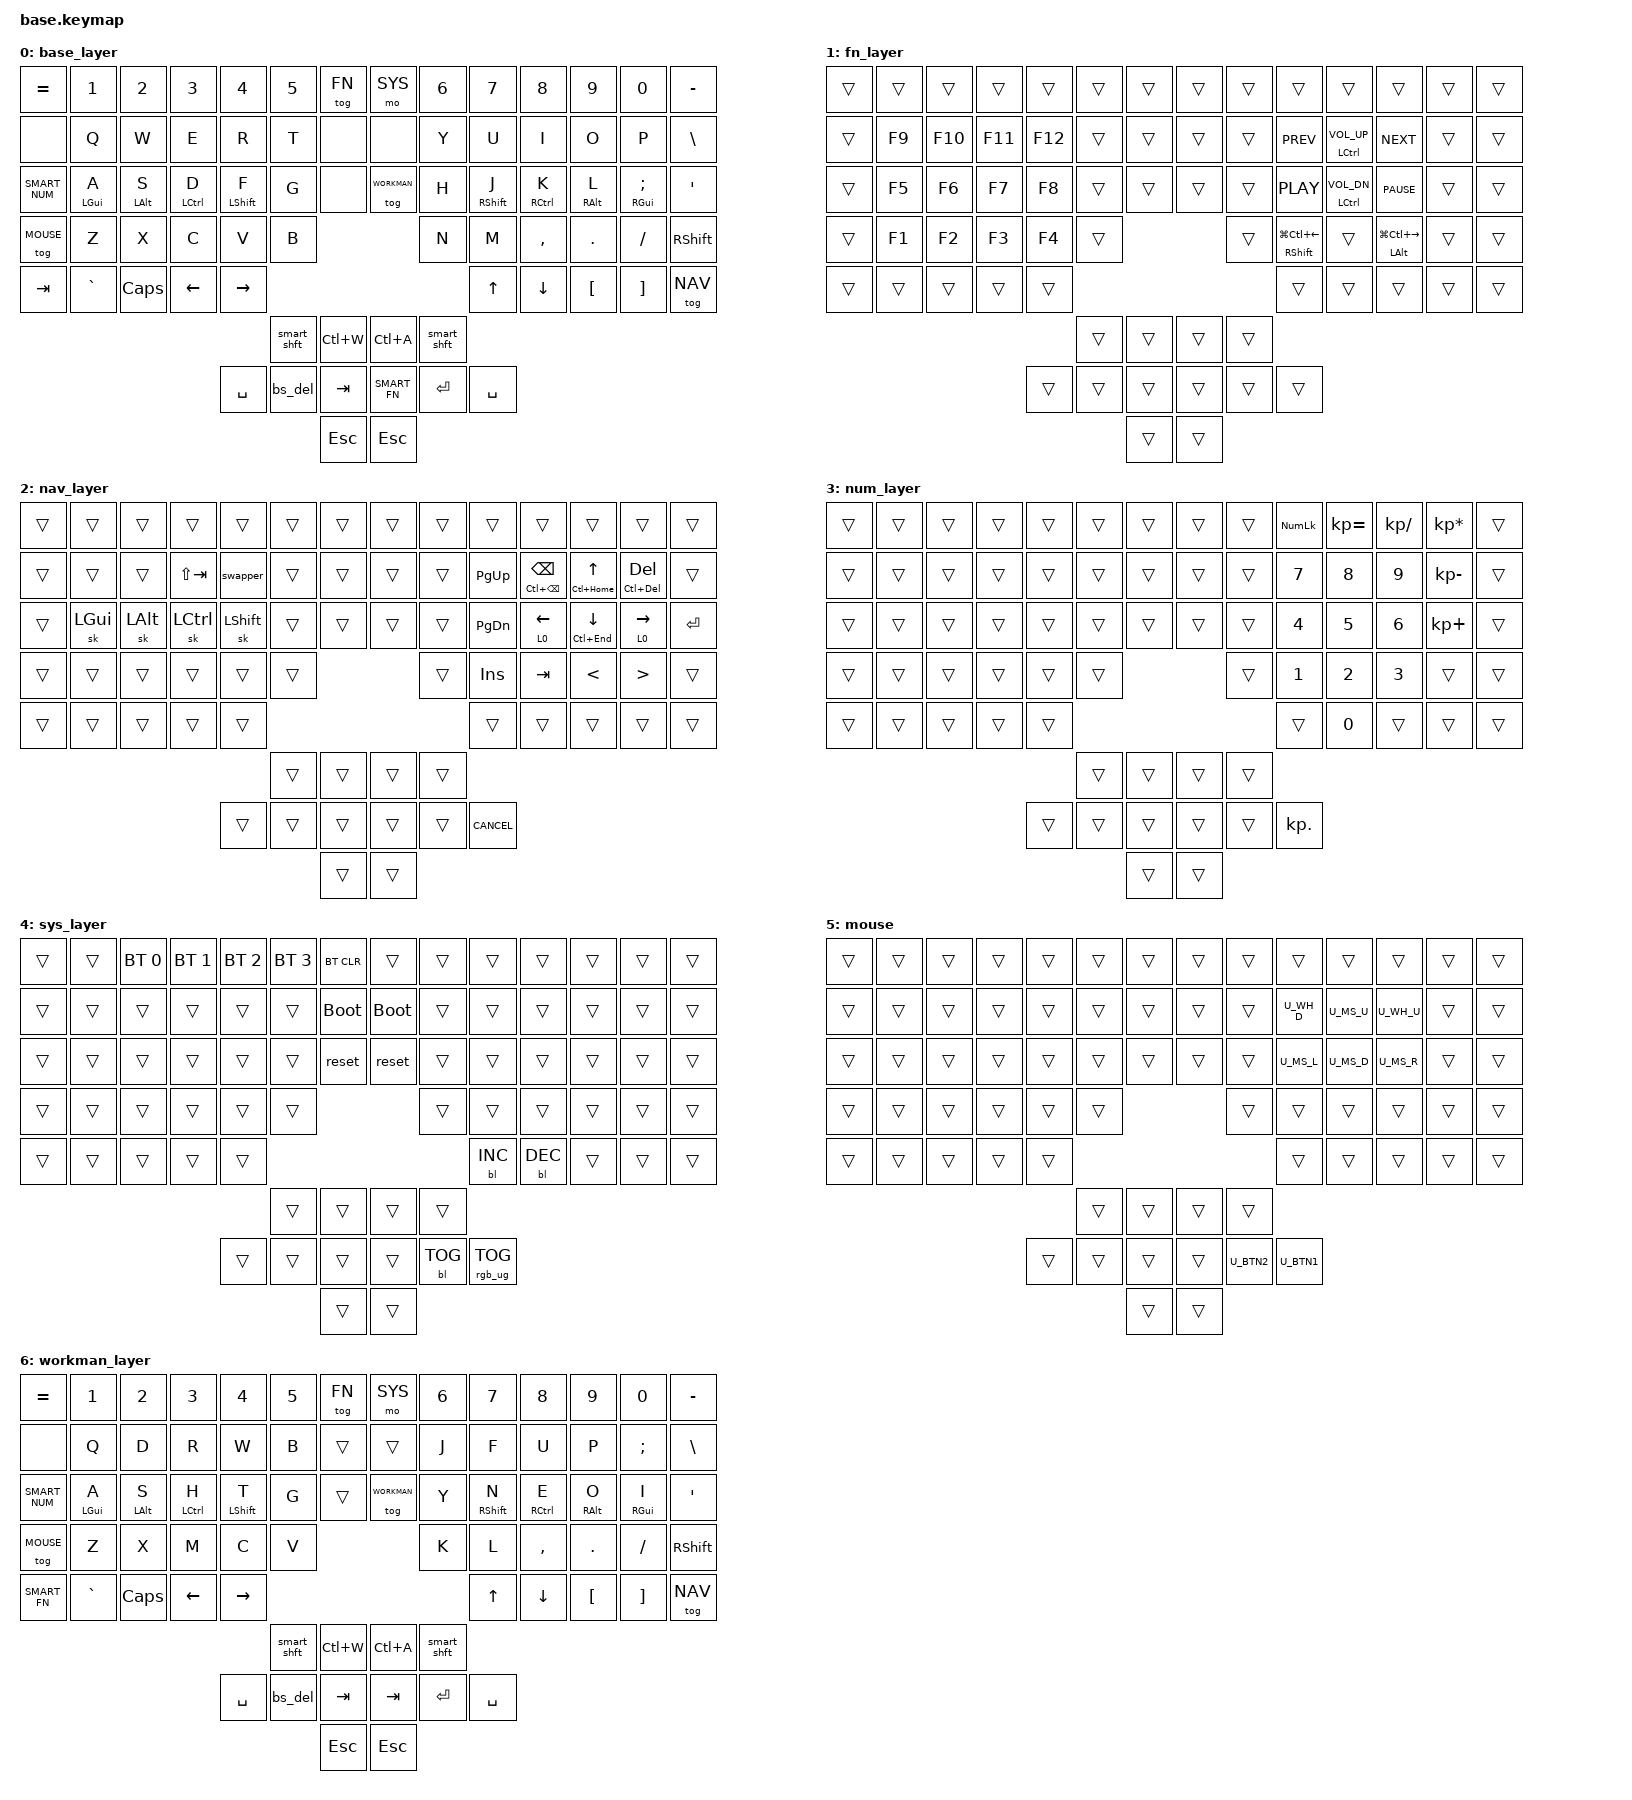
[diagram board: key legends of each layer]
#include <behaviors.dtsi>
#include <dt-bindings/zmk/keys.h>
#if CONFIG_WIRELESS
    #include <dt-bindings/zmk/bt.h>
    #define _BT_SEL_KEYS_ &bt BT_SEL 0 &bt BT_SEL 1 &bt BT_SEL 2 &bt BT_SEL 3 &bt BT_CLR
#else
    #define _BT_SEL_KEYS_ &trans &trans &trans &trans &trans
#endif

#include "../zmk-nodefree-config/helper.h"
#include "../zmk-nodefree-config/international_chars/greek.dtsi"
#include "../zmk-nodefree-config/international_chars/german.dtsi"

#define XXX &none
#define ___ &trans

/* Global settings */

#define QUICK_TAP_MS 175

#define DEF 0
#define FN 1
#define NAV 2
#define NUM 3
#define SYS 4
#define MOUSE 5
#define WORKMAN 6

#include "extra_keys.h"

#include "behaviours/morphs.dtsi"
#include "behaviours/tap_dance.dtsi"

#include "behaviours/smart_mouse.dtsi"
#include "behaviours/smart_num.dtsi"
#include "behaviours/smart_shift.dtsi"
#include "behaviours/smart_fn.dtsi"

#include "mouse.dtsi"

&sk {  // sticky-key config
    release-after-ms = <900>;  // release after 0.6s
    quick-release;             // no double capitalization when rolling keys
};

&sl {  // sticky-layer config
    ignore-modifiers;          // allow chording sticky mods & layers
};

&lt {  // layer-tap config
    flavor = "balanced";
    tapping-term-ms = <200>;
    quick-tap-ms = <QUICK_TAP_MS>;
};

/* Homerow mods */

#define KEYS_L LT0 LT1 LT2 LT3 LT4 LM0 LM1 LM2 LM3 LM4 LB0 LB1 LB2 LB3 LB4  // left hand
#define KEYS_R RT0 RT1 RT2 RT3 RT4 RM0 RM1 RM2 RM3 RM4 RB0 RB1 RB2 RB3 RB4  // right hand
#define THUMBS LH2 LH1 LH0 RH0 RH1 RH2                                      // thumbs

#define MAKE_HRM(NAME, HOLD, TAP, TRIGGER_POS) \
    ZMK_BEHAVIOR(NAME, hold_tap, \
        flavor = "balanced"; \
        tapping-term-ms = <280>; \
        quick-tap-ms = <QUICK_TAP_MS>; \
        global-quick-tap-ms = <150>; \
        bindings = <HOLD>, <TAP>; \
        hold-trigger-key-positions = <TRIGGER_POS>; \
        hold-trigger-on-release; \
    )
MAKE_HRM(hml, &kp, &kp, KEYS_R THUMBS)  // left-hand HRMs
MAKE_HRM(hmr, &kp, &kp, KEYS_L THUMBS)  // right-hand HRMs

MAKE_HRM(hml_repeat, &kp, &key_repeat, KEYS_R THUMBS)  // used for HRM-combo
MAKE_HRM(hmr_lpar_lt, &kp, &lpar_lt, KEYS_L THUMBS)    // "    "   "   "
MAKE_HRM(hmr_rpar_gt, &kp, &rpar_gt, KEYS_L THUMBS)    // "    "   "   "

/* Nav cluster */

// long-tap action on hold, short-tap action on all interrupts
#define MT_CORE \
    flavor = "tap-preferred"; \
    tapping-term-ms = <220>; \
    quick-tap-ms = <220>; \
    hold-trigger-key-positions = <0>;

&mt { MT_CORE };
ZMK_BEHAVIOR(mt_home, hold_tap, bindings = <&masked_home>, <&kp>; MT_CORE)
ZMK_BEHAVIOR(mt_end,  hold_tap,  bindings = <&masked_end>, <&kp>; MT_CORE)

#define NAV_LEFT  &mt_home 0   LEFT    // tap: left  | long-tap: beginning of line
#define NAV_RIGHT &mt_end 0    RIGHT   // tap: right | long-tap: end       of line
#define NAV_UP    &mt LC(HOME) UP      // tap: up    | long-tap: beginning of document
#define NAV_DOWN  &mt LC(END)  DOWN    // tap: down  | long-tap: end       of document
#define NAV_BSPC  &mt LC(BSPC) BSPC    // tap: bspc  | long-tap: delete word backward
#define NAV_DEL   &mt LC(DEL)  DEL     // tap: del   | long-tap: delete word forward

// mask CTRL when holding left/right to avoid accidental jumps to beginning/end of document
#define MASK_MODS(NAME, MODS, BINDING) \
    ZMK_BEHAVIOR(NAME, mod_morph, \
        bindings = <BINDING>, <BINDING>; \
        mods = <MODS>; \
    )
MASK_MODS(masked_home, (MOD_LCTL), &kp HOME)
MASK_MODS(masked_end,  (MOD_LCTL), &kp END)

/* Caps-word, num-word and smart-mouse */

/* Custom behaviors */

// Alt+Tab swapper, requires PR #1366
ZMK_BEHAVIOR(swapper, tri_state,
    bindings = <&kt LCMD>, <&kp TAB>, <&kt LCMD>;
    ignored-key-positions = <LT2>;
)

ZMK_BEHAVIOR(back, tri_state,
    bindings = <&kt LCMD>, <&kp LEFT_BRACKET>, <&kt LCMD>;
    ignored-key-positions = <LT2>;
)

ZMK_BEHAVIOR(forward, tri_state,
    bindings = <&kt LCMD>, <&kp LEFT_BRACKET>, <&kt LCMD>;
    ignored-key-positions = <LT2>;
)

#define MEH(key) LA(LS(LC(key))) //, used like &kp MEH(Q)

// misc aliases
#define CANCEL      &kp K_CANCEL             // cancel caps-word, num-word and smart-mouse

#define PLAY        &kp C_PLAY               // play
#define PAUSE       &kp C_PAUSE              // pause

#define PREV        &kp C_PREV               // previous track
#define NEXT        &kp C_NEXT               // next track

#define VOL_UP      &hmr LCTRL C_VOL_UP
#define VOL_DOWN    &hmr LCTRL C_VOL_DN

#define DSK_PREV    &hmr RSHFT LG(LC(LEFT))  // previous desktop
#define DSK_NEXT    &hmr LALT LG(LC(RIGHT))  // next     desktop

#define VIM_WIN     &kp LC(W)                // vim window  mode

#define TMUX_CMD    &kp LC(A)                // tmux command mode

#include "combos.dtsi"  // requires layer aliases

/* Keymap */
ZMK_CONDITIONAL_LAYER(FN NUM, SYS)  // FN + NUM --> SYS


// ╭────────────────────────────┬────────────────────────────╮
// │  0   1   2   3   4   5   6 │  7   8   9  10  11  12  13 │
// │ 14  15  16  17  18  19  20 │ 21  22  23  24  25  26  27 │
// │ 28  29  30  31  32  33  34 │ 35  36  37  38  39  40  41 │
// │ 42  43  44  45  46  47 ╭───┴───╮ 48  49  50  51  52  53 │
// │ 54  55  56  57  58╭────╯       ╰────╮59  60  61  62  63 │
// ╰────────────┼────────┬────────┼──────────────────────────╯
//                 ╭───╯ 64  65 │ 66  67 ╰───╮
//                 │ 68  69  70 │ 71  72  73 │
//                 ╰───────╮ 74 │ 75 ╭───────╯
//                         ╰────│────╯



/* use urob's layout for Advantage 360 pro */
/ {
    /* remove unused keys from layout and move thumb cluster to bottom */
    chosen {
        zmk,matrix_transform = &urobs_transform;
    };

    behaviors {
      #include "macros.dtsi"
    };


    keymap {
        compatible = "zmk,keymap";

        base_layer {
            bindings = <
            //╭─────────────┬─────────────┬─────────────┬─────────────┬─────────────┬─────────────┬─────────────╮    ╭─────────────┬─────────────┬─────────────┬─────────────┬─────────────┬────────────────┬──────────╮
                &kp EQUAL     &kp N1         &kp N2        &kp N3        &kp N4         &kp N5       &tog FN             &mo SYS       &kp N6       &kp N7         &kp N8        &kp N9        &kp N0        &kp MINUS
            //├─────────────├─────────────┼─────────────┼─────────────┼─────────────┼─────────────┤─────────────┤    ├─────────────├─────────────┼─────────────┼─────────────┼─────────────┼────────────────┤──────────┤
                &none         &kp Q          &kp W         &kp E         &kp R          &kp T        &none               &none         &kp Y        &kp U          &kp I         &kp O         &kp P          &kp BSLH
            //├─────────────├─────────────┼─────────────┼─────────────┼─────────────┼─────────────┤─────────────┤    ├─────────────├─────────────┼─────────────┼─────────────┼─────────────┼────────────────┤──────────┤
                SMART_NUM     &hml LGUI A   &hml LALT S   &hml LCTRL D  &hml LSHIFT F   &kp G        &none             &tog WORKMAN     &kp H     &hmr RSHIFT J  &hmr RCTRL K  &hmr RALT L   &hmr RGUI SEMI   &kp SQT
            //├─────────────├─────────────┼─────────────┼─────────────┼─────────────┼─────────────╭─────────────┴────┴─────────────├─────────────┼─────────────┼─────────────┼─────────────┼────────────────┤──────────┤
                &tog MOUSE    &kp Z          &kp X         &kp C         &kp V          &kp B                                          &kp N        &kp M        &kp COMMA      &kp DOT       &kp FSLH       &kp RSHFT
            //├─────────────├─────────────┼─────────────┼─────────────┼─────────────╭─────────────╯                                ╰─────────────╮─────────────┼─────────────┼─────────────┼────────────────┤──────────┤
                &kp TAB       &kp GRAVE      &kp CAPS      &kp LEFT      &kp RIGHT                                                                  &kp UP        &kp DOWN      &kp LBKT      &kp RBKT        &tog NAV
            //╰─────────────┴─────────────┴─────────────┴──────────────────────────────────────────────────────────────────────────────────────────────────────┴─────────────┴─────────────┴────────────────┴──────────╯
                                                                                      &smart_shft   VIM_WIN           TMUX_CMD       &smart_shft
            //                                                        ╭─────────────╯                             │                              ╰─────────────╮
                                                                         &kp SPACE    &bs_del       &kp TAB           SMART_FN        &kp ENTER     &kp SPACE
            //                                                        ╰───────────────────────────╮               │               ╭────────────────────────────╯
                                                                                                    &kp ESC           &kp ESC
            //                                                                                    ╰───────────────┴───────────────╯
            >;
        };

        fn_layer {
            bindings = <
            //╭─────────────┬─────────────┬─────────────┬─────────────┬─────────────┬─────────────┬─────────────╮    ╭─────────────┬─────────────┬─────────────┬─────────────┬─────────────┬────────────────┬──────────╮
                   ___        ___           ___            ___           ___           ___          ___                ___           ___            ___           ___          ___           ___              ___
            //├─────────────├─────────────┼─────────────┼─────────────┼─────────────┼─────────────┤─────────────┤    ├─────────────├─────────────┼─────────────┼─────────────┼─────────────┼────────────────┤──────────┤
                   ___        &kp F9        &kp F10        &kp F11       &kp F12       ___           ___               ___           ___            PREV          VOL_UP       NEXT          ___              ___
            //├─────────────├─────────────┼─────────────┼─────────────┼─────────────┼─────────────┤─────────────┤    ├─────────────├─────────────┼─────────────┼─────────────┼─────────────┼────────────────┤──────────┤
                   ___        &kp F5        &kp F6         &kp F7        &kp F8        ___           ___               ___           ___            PLAY          VOL_DOWN     PAUSE         ___              ___
            //├─────────────├─────────────┼─────────────┼─────────────┼─────────────┼─────────────╭─────────────┴────┴─────────────├─────────────┼─────────────┼─────────────┼─────────────┼────────────────┤──────────┤
                   ___        &kp F1        &kp F2         &kp F3        &kp F4        ___                                            ___           DSK_PREV      ___          DSK_NEXT      ___              ___
            //├─────────────├─────────────┼─────────────┼─────────────┼─────────────╭─────────────╯                                ╰─────────────╮─────────────┼─────────────┼─────────────┼────────────────┤──────────┤
                   ___        ___           ___            ___          ___                                                                         ___           ___          ___           ___              ___
            //╰─────────────┴─────────────┴─────────────┴────────────────────────────────────────────────────────────────────────────────────────┴─────────────┴─────────────┴─────────────┴────────────────┴──────────╯
                                                                                      ___           ___                ___           ___
            //                                                        ╭─────────────╯                               │                            ╰─────────────╮
                                                                        ___           ___           ___                ___           ___          ___
            //                                                        ╰───────────────────────────╮                 │               ╭──────────────────────────╯
                                                                                                    ___                ___
            //                                                                                    ╰─────────────────┴───────────────╯
            >;
        };

        nav_layer {
            bindings = <
            //╭─────────────┬─────────────┬─────────────┬─────────────┬─────────────┬─────────────┬─────────────╮    ╭─────────────┬─────────────┬─────────────┬─────────────┬─────────────┬────────────────┬──────────╮
                   ___        ___           ___            ___          ___           ___           ___                ___            ___          ___           ___           ___           ___              ___
            //├─────────────├─────────────┼─────────────┼─────────────┼─────────────┼─────────────┤─────────────┤    ├─────────────├─────────────┼─────────────┼─────────────┼─────────────┼────────────────┤──────────┤
                   ___        ___           ___            &kp LS(TAB)  &swapper      ___           ___                ___            ___          &kp PG_UP     NAV_BSPC      NAV_UP        NAV_DEL          ___
            //├─────────────├─────────────┼─────────────┼─────────────┼─────────────┼─────────────┤─────────────┤    ├─────────────├─────────────┼─────────────┼─────────────┼─────────────┼────────────────┤──────────┤
                   ___        &sk LGUI      &sk LALT      &sk LCTRL     &sk LSHFT     ___           ___                ___            ___          &kp PG_DN     NAV_LEFT      NAV_DOWN      NAV_RIGHT        &kp RET
            //├─────────────├─────────────┼─────────────┼─────────────┼─────────────┼─────────────╭─────────────┴────┴─────────────├─────────────┼─────────────┼─────────────┼─────────────┼────────────────┤──────────┤
                   ___        ___           ___            ___          ___           ___                                             ___          &kp INS       &kp TAB       &kp LT        &kp GT           ___
            //├─────────────├─────────────┼─────────────┼─────────────┼─────────────╭─────────────╯                                ╰─────────────╮─────────────┼─────────────┼─────────────┼────────────────┤──────────┤
                   ___        ___           ___            ___          ___                                                                        ___           ___           ___           ___              ___
            //╰─────────────┴─────────────┴─────────────┴────────────────────────────────────────────────────────────────────────────────────────┴─────────────┴─────────────┴─────────────┴────────────────┴──────────╯
                                                                                      ___           ___                ___            ___
            //                                                        ╭─────────────╯                               │                            ╰─────────────╮
                                                                        ___           ___           ___                ___            ___           CANCEL
            //                                                        ╰───────────────────────────╮                 │               ╭──────────────────────────╯
                                                                                                    ___                ___
            //                                                                                    ╰─────────────────┴───────────────╯
            >;
        };

        num_layer {
            bindings = <
          //╭─────────────┬─────────────┬─────────────┬─────────────┬─────────────┬─────────────┬─────────────╮    ╭─────────────┬─────────────┬─────────────┬─────────────┬─────────────┬────────────────┬──────────╮
                 ___        ___           ___            ___           ___           ___          ___                ___           ___           &kp KP_NUM    &kp KP_EQUAL  &kp KP_DIVIDE &kp KP_MULTIPLY  ___
          //├─────────────├─────────────┼─────────────┼─────────────┼─────────────┼─────────────┤─────────────┤    ├─────────────├─────────────┼─────────────┼─────────────┼─────────────┼────────────────┤──────────┤
                 ___        ___           ___            ___          ___           ___           ___                ___           ___           &kp N7        &kp N8        &kp N9        &kp KP_MINUS     ___
          //├─────────────├─────────────┼─────────────┼─────────────┼─────────────┼─────────────┤─────────────┤    ├─────────────├─────────────┼─────────────┼─────────────┼─────────────┼────────────────┤──────────┤
                 ___        ___           ___            ___          ___           ___           ___                ___           ___           &kp N4        &kp N5        &kp N6        &kp KP_PLUS      ___
          //├─────────────├─────────────┼─────────────┼─────────────┼─────────────┼─────────────╭─────────────┴────┴─────────────├─────────────┼─────────────┼─────────────┼─────────────┼────────────────┤──────────┤
                 ___        ___           ___            ___          ___           ___                                            ___           &kp N1        &kp N2        &kp N3        ___              ___
          //├─────────────├─────────────┼─────────────┼─────────────┼─────────────╭─────────────╯                                ╰─────────────╮─────────────┼─────────────┼─────────────┼────────────────┤──────────┤
                 ___        ___           ___            ___          ___                                                                        ___           &kp N0        ___           ___              ___
          //╰─────────────┴─────────────┴─────────────┴────────────────────────────────────────────────────────────────────────────────────────┴─────────────┴─────────────┴─────────────┼────────────────┴──────────╯
                                                                                    ___           ___                ___           ___
          //                                                        ╭─────────────╯                               │                            ╰─────────────╮
                                                                      ___           ___           ___                ___           ___           &kp KP_DOT
          //                                                        ╰───────────────────────────╮                 │               ╭──────────────────────────╯
                                                                                                  ___                ___
          //                                                                                    ╰─────────────────┴───────────────╯
            >;
        };

        sys_layer {
            bindings = <
          //╭─────────────┬─────────────┬─────────────┬─────────────┬─────────────┬─────────────┬─────────────╮    ╭─────────────┬─────────────┬─────────────┬─────────────┬─────────────┬────────────────┬──────────╮
                 ___        ___           &bt BT_SEL 0  &bt BT_SEL 1  &bt BT_SEL 2  &bt BT_SEL 3  &bt BT_CLR         ___           ___           ___           ___           ___           ___               ___
          //├─────────────├─────────────┼─────────────┼─────────────┼─────────────┼─────────────┤─────────────┤    ├─────────────├─────────────┼─────────────┼─────────────┼─────────────┼────────────────┤──────────┤
                 ___        ___           ___            ___          ___           ___           &bootloader        &bootloader   ___           ___           ___           ___           ___               ___
          //├─────────────├─────────────┼─────────────┼─────────────┼─────────────┼─────────────┤─────────────┤    ├─────────────├─────────────┼─────────────┼─────────────┼─────────────┼────────────────┤──────────┤
                 ___        ___           ___            ___          ___           ___           &reset             &reset        ___           ___           ___           ___           ___               ___
          //├─────────────├─────────────┼─────────────┼─────────────┼─────────────┼─────────────╭─────────────┴────┴─────────────├─────────────┼─────────────┼─────────────┼─────────────┼────────────────┤──────────┤
                 ___        ___           ___            ___          ___           ___                                            ___           ___           ___           ___           ___               ___
          //├─────────────├─────────────┼─────────────┼─────────────┼─────────────╭─────────────╯                                ╰─────────────╮─────────────┼─────────────┼─────────────┼────────────────┤──────────┤
                 ___        ___           ___            ___          ___                                                                        &bl BL_INC   &bl BL_DEC     ___           ___               ___
          //╰─────────────┴─────────────┴─────────────┴────────────────────────────────────────────────────────────────────────────────────────┴─────────────┴─────────────┴─────────────┴────────────────┴──────────╯
                                                                                    ___           ___                ___           ___
          //                                                        ╭─────────────╯                               │                            ╰─────────────╮
                                                                      ___           ___           ___                ___            &bl BL_TOG  &rgb_ug RGB_TOG
          //                                                        ╰───────────────────────────╮                 │               ╭──────────────────────────╯
                                                                                                  ___                ___
          //                                                                                    ╰─────────────────┴───────────────╯
            >;
        };

        mouse {
            bindings = <
          //╭─────────────┬─────────────┬─────────────┬─────────────┬─────────────┬─────────────┬─────────────╮    ╭─────────────┬─────────────┬─────────────┬─────────────┬─────────────┬────────────────┬──────────╮
                 ___        ___           ___            ___          ___           ___           ___                ___            ___          ___           ___           ___           ___              ___
          //├─────────────├─────────────┼─────────────┼─────────────┼─────────────┼─────────────┤─────────────┤    ├─────────────├─────────────┼─────────────┼─────────────┼─────────────┼────────────────┤──────────┤
                 ___        ___           ___            ___          ___           ___           ___                ___            ___          U_WH_D        U_MS_U        U_WH_U        ___              ___
          //├─────────────├─────────────┼─────────────┼─────────────┼─────────────┼─────────────┤─────────────┤    ├─────────────├─────────────┼─────────────┼─────────────┼─────────────┼────────────────┤──────────┤
                 ___        ___           ___            ___          ___           ___           ___                ___            ___          U_MS_L        U_MS_D        U_MS_R        ___              ___
          //├─────────────├─────────────┼─────────────┼─────────────┼─────────────┼─────────────╭─────────────┴────┴─────────────├─────────────┼─────────────┼─────────────┼─────────────┼────────────────┤──────────┤
                 ___        ___           ___            ___          ___           ___                                             ___          ___           ___           ___           ___              ___
          //├─────────────├─────────────┼─────────────┼─────────────┼─────────────╭─────────────╯                                ╰─────────────╮─────────────┼─────────────┼─────────────┼────────────────┤──────────┤
                 ___        ___           ___            ___          ___                                                                        ___           ___           ___           ___              ___
          //╰─────────────┴─────────────┴─────────────┴────────────────────────────────────────────────────────────────────────────────────────┴─────────────┴─────────────┴─────────────┴────────────────┴──────────╯
                                                                                    ___           ___                ___            ___
          //                                                        ╭─────────────╯                               │                            ╰─────────────╮
                                                                      ___           ___           ___                ___            U_BTN2       U_BTN1
          //                                                        ╰───────────────────────────╮                 │               ╭──────────────────────────╯
                                                                                                  ___                ___
          //                                                                                    ╰─────────────────┴───────────────╯
            >;
        };

      workman_layer {
          bindings = <
        //╭─────────────┬─────────────┬─────────────┬─────────────┬─────────────┬─────────────┬─────────────╮    ╭─────────────┬─────────────┬─────────────┬─────────────┬─────────────┬────────────────┬──────────╮
            &kp EQUAL     &kp N1         &kp N2        &kp N3        &kp N4         &kp N5       &tog FN             &mo SYS       &kp N6       &kp N7         &kp N8        &kp N9        &kp N0        &kp MINUS
        //├─────────────├─────────────┼─────────────┼─────────────┼─────────────┼─────────────┤─────────────┤    ├─────────────├─────────────┼─────────────┼─────────────┼─────────────┼────────────────┤──────────┤
            &none         &kp Q         &kp D          &kp R        &kp W         &kp B         ___                ___            &kp J        &kp F         &kp U         &kp P         &kp SEMICOLON    &kp BSLH
        //├─────────────├─────────────┼─────────────┼─────────────┼─────────────┼─────────────┤─────────────┤    ├─────────────├─────────────┼─────────────┼─────────────┼─────────────┼────────────────┤──────────┤
            SMART_NUM     &hml LGUI A   &hml LALT S    &hml LCTRL H &hml LSHIFT T &kp G         ___                &tog WORKMAN   &kp Y       &hmr RSHIFT N  &hmr RCTRL E  &hmr RALT O   &hmr RGUI I      &kp SQT
        //├─────────────├─────────────┼─────────────┼─────────────┼─────────────┼─────────────╭─────────────┴────┴─────────────├─────────────┼─────────────┼─────────────┼─────────────┼────────────────┤──────────┤
            &tog MOUSE    &kp Z         &kp X          &kp M        &kp C         &kp V                                           &kp K        &kp L         &kp COMMA     &kp PERIOD    &kp SLASH        &kp RSHFT
        //├─────────────├─────────────┼─────────────┼─────────────┼─────────────╭─────────────╯                                ╰─────────────╮─────────────┼─────────────┼─────────────┼────────────────┤──────────┤
            SMART_FN      &kp GRAVE     &kp CAPS      &kp LEFT      &kp RIGHT                                                                   &kp UP        &kp DOWN       &kp LBKT      &kp RBKT       &tog NAV
        //╰─────────────┴─────────────┴─────────────┴────────────────────────────────────────────────────────────────────────────────────────┴─────────────┴─────────────┴─────────────┴────────────────┴──────────╯
                                                                                  &smart_shft   VIM_WIN           TMUX_CMD       &smart_shft
        //                                                        ╭─────────────╯                               │                            ╰─────────────╮
                                                                    &kp SPACE    &bs_del       &kp TAB           &kp TAB         &kp ENTER    &kp SPACE
        //                                                        ╰───────────────────────────╮                 │               ╭──────────────────────────╯
                                                                                                &kp ESC           &kp ESC
        //                                                                                    ╰─────────────────┴───────────────╯
          >;
      };

        // mouse layer
        // mouse {
        //     bindings = <
        //╭─────────────┬─────────────┬─────────────┬─────────────┬─────────────┬─────────────┬─────────────╮    ╭─────────────┬─────────────┬─────────────┬─────────────┬─────────────┬────────────────┬──────────╮
        //     ___        ___           ___            ___          ___           ___           ___                ___            ___          ___           ___           ___           ___              ___
        //├─────────────├─────────────┼─────────────┼─────────────┼─────────────┼─────────────┤─────────────┤    ├─────────────├─────────────┼─────────────┼─────────────┼─────────────┼────────────────┤──────────┤
        //     ___        ___           ___            ___          ___           ___           ___                ___            ___          ___           ___           ___           ___               ___
        //├─────────────├─────────────┼─────────────┼─────────────┼─────────────┼─────────────┤─────────────┤    ├─────────────├─────────────┼─────────────┼─────────────┼─────────────┼────────────────┤──────────┤
        //     ___        ___           ___            ___          ___           ___           ___                ___            ___          ___           ___           ___           ___               ___
        //├─────────────├─────────────┼─────────────┼─────────────┼─────────────┼─────────────╭─────────────┴────┴─────────────├─────────────┼─────────────┼─────────────┼─────────────┼────────────────┤──────────┤
        //     ___        ___           ___            ___          ___           ___                                             ___          ___           ___           ___           ___               ___
        //├─────────────├─────────────┼─────────────┼─────────────┼─────────────╭─────────────╯                                ╰────────────╮┼─────────────┼─────────────┼─────────────┼────────────────┤──────────┤
        //     ___        ___           ___            ___          ___                                                                        ___           ___           ___           ___               ___
        //╰─────────────┴─────────────┴─────────────┴────────────────────────────────────────────────────────────────────────────────────────┴─────────────┴─────────────┴─────────────┴────────────────┴──────────╯
        //                                                                        ___           ___                ___            ___
        //                                                        ╭─────────────╯                               │                           ╰────────────╮
        //                                                          ___           ___           ___                ___            ___          ___
        //                                                        ╰───────────────────────────╮                 │               ╭────────────────────────╯
        //                                                                                      ___                ___
        //                                                                                    ╰─────────────────┴───────────────╯
        //    >;
        //};
    };

};


/* vim: set ft=c tw=174: */
